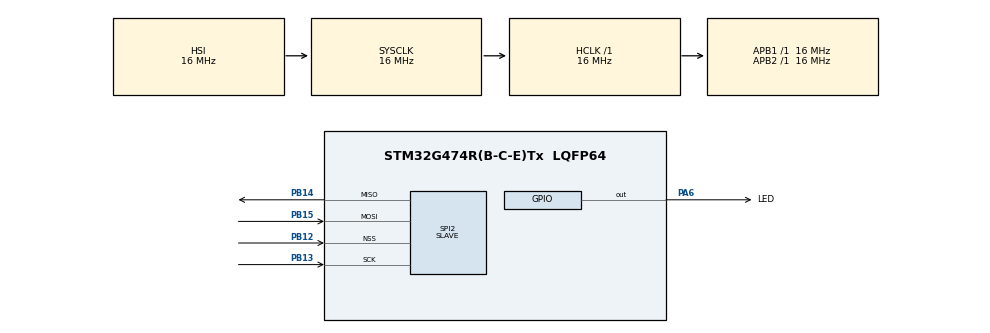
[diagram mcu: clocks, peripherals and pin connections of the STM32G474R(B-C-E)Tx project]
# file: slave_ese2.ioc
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Mcu.Family=STM32G4
Mcu.Name=STM32G474R(B-C-E)Tx
Mcu.Package=LQFP64
NVIC.PriorityGroup=NVIC_PRIORITYGROUP_4
NVIC.SPI2_IRQn=true\:0\:0\:false\:false\:true\:true\:true\:true
PA6.GPIO_Label=LED
PA6.Signal=GPIO_Output
PB12.Mode=NSS_Signal_Hard_Input
PB12.Signal=SPI2_NSS
PB13.Mode=Full_Duplex_Slave
PB13.Signal=SPI2_SCK
PB14.Mode=Full_Duplex_Slave
PB14.Signal=SPI2_MISO
PB15.Mode=Full_Duplex_Slave
PB15.Signal=SPI2_MOSI
ProjectManager.HeapSize=0x200
ProjectManager.StackSize=0x400
ProjectManager.TargetToolchain=STM32CubeIDE
RCC.AHBFreq_Value=16000000
RCC.APB1Freq_Value=16000000
RCC.APB1TimFreq_Value=16000000
RCC.APB2Freq_Value=16000000
RCC.APB2TimFreq_Value=16000000
RCC.CortexFreq_Value=16000000
RCC.EXTERNAL_CLOCK_VALUE=12288000
RCC.HCLKFreq_Value=16000000
RCC.HSE_VALUE=8000000
RCC.HSI48_VALUE=48000000
RCC.HSI_VALUE=16000000
RCC.LSE_VALUE=32768
RCC.SYSCLKFreq_VALUE=16000000
RCC.USBFreq_Value=64000000
RCC.VCOOutputFreq_Value=128000000
SPI2.DataSize=SPI_DATASIZE_8BIT
SPI2.Direction=SPI_DIRECTION_2LINES
SPI2.Mode=SPI_MODE_SLAVE
SPI2.VirtualNSS=VM_NSSHARD
SPI2.VirtualType=VM_SLAVE
VP_SYS_VS_DBSignals.Mode=DisableDeadBatterySignals
board=custom

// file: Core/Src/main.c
/* USER CODE BEGIN Header */
/**
  ******************************************************************************
  * @file           : main.c
  * @brief          : Main program body
  ******************************************************************************
  * @attention
  *
  * Copyright (c) 2026 STMicroelectronics.
  * All rights reserved.
  *
  * This software is licensed under terms that can be found in the LICENSE file
  * in the root directory of this software component.
  * If no LICENSE file comes with this software, it is provided AS-IS.
  *
  ******************************************************************************
  */
/* USER CODE END Header */
#include "main.h"
#include "spi.h"
#include "gpio.h"

/* USER CODE BEGIN PV */
volatile uint8_t n_rx = 0;         // Buffer per ricevere il coefficiente dal Master
volatile uint8_t n_tx = 0;         // Buffer per inviare la risposta incrementata (n + 1)

volatile uint32_t half_period = 500;
/* USER CODE END PV */

void SystemClock_Config(void);

int main(void)
{

  /* MCU Configuration--------------------------------------------------------*/

  /* Reset of all peripherals, Initializes the Flash interface and the Systick. */
  HAL_Init();

  /* Configure the system clock */
  SystemClock_Config();

  /* Initialize all configured peripherals */
  MX_GPIO_Init();
  MX_SPI2_Init();
  /* USER CODE BEGIN 2 */

  //riarmo subito lo slave, si mette già in ascolto e vuole già inviare e riceve,
  //inizierà la comunicazione non appena NSS del master sarà basso
  HAL_SPI_TransmitReceive_IT(&hspi2, (uint8_t*)&n_tx, (uint8_t*)&n_rx, 1);

  /* USER CODE END 2 */

  /* Infinite loop */
  while (1)
  {

    /* USER CODE BEGIN 3 */
	HAL_GPIO_TogglePin(LED_GPIO_Port, LED_Pin);
	HAL_Delay(half_period);
  }
  /* USER CODE END 3 */
}

void SystemClock_Config(void)
{
  RCC_OscInitTypeDef RCC_OscInitStruct = {0};
  RCC_ClkInitTypeDef RCC_ClkInitStruct = {0};

  /** Configure the main internal regulator output voltage
  */
  HAL_PWREx_ControlVoltageScaling(PWR_REGULATOR_VOLTAGE_SCALE1);

  /** Initializes the RCC Oscillators according to the specified parameters
  * in the RCC_OscInitTypeDef structure.
  */
  RCC_OscInitStruct.OscillatorType = RCC_OSCILLATORTYPE_HSI;
  RCC_OscInitStruct.HSIState = RCC_HSI_ON;
  RCC_OscInitStruct.HSICalibrationValue = RCC_HSICALIBRATION_DEFAULT;
  RCC_OscInitStruct.PLL.PLLState = RCC_PLL_NONE;
  if (HAL_RCC_OscConfig(&RCC_OscInitStruct) != HAL_OK)
  {
    Error_Handler();
  }

  /** Initializes the CPU, AHB and APB buses clocks
  */
  RCC_ClkInitStruct.ClockType = RCC_CLOCKTYPE_HCLK|RCC_CLOCKTYPE_SYSCLK
                              |RCC_CLOCKTYPE_PCLK1|RCC_CLOCKTYPE_PCLK2;
  RCC_ClkInitStruct.SYSCLKSource = RCC_SYSCLKSOURCE_HSI;
  RCC_ClkInitStruct.AHBCLKDivider = RCC_SYSCLK_DIV1;
  RCC_ClkInitStruct.APB1CLKDivider = RCC_HCLK_DIV1;
  RCC_ClkInitStruct.APB2CLKDivider = RCC_HCLK_DIV1;

  if (HAL_RCC_ClockConfig(&RCC_ClkInitStruct, FLASH_LATENCY_0) != HAL_OK)
  {
    Error_Handler();
  }
}

/* USER CODE BEGIN 4 */
void HAL_SPI_TxRxCpltCallback(SPI_HandleTypeDef *hspi) {
	if (hspi->Instance == SPI2) {
		//una volta ricevuto o inviato il parametro
		//aumento +1 quello ricevuto
		n_tx=n_rx+1;
		if(n_tx>0){
			half_period=500/n_tx;
		}
		//riarmo la trasmissione per inviare il nuovo n_tx
		HAL_SPI_TransmitReceive_IT(&hspi2, (uint8_t*)&n_tx, (uint8_t*)&n_rx, 1);
	}
}

/* USER CODE END 4 */

void Error_Handler(void)
{
  __disable_irq();
  while (1)
  {
  }
}
